# MIK32 register map
Vendor: Mikron; Series: MIK32; File version: 1.0
Registers are 32-bit, read-write, reset 0x0 unless marked. A register's access mark holds for its fields unless they carry their own. Offsets are from the block's base; [hi:lo] are bit positions.

## WakeUp — Блок WakeUp - управление питанием системным доменом, управление источниками тактовых сигналов
Base 0x00060000
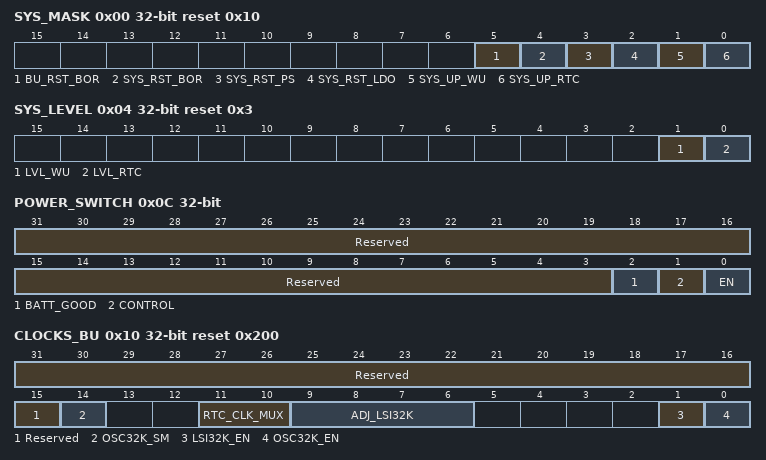
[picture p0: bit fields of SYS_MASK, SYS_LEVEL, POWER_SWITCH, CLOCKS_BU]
0x00 SYS_MASK reset 0x10 — Маски событий для включения и сброса системного домена
  [5] BU_RST_BOR — Запрещение формирования сброса батарейного домена при появлении сигнала BOR
    1=Disable (Запрещено); 0=Enable (Разрешено)
  [4] SYS_RST_BOR — Запрещение формирования сброса системного домена при появлении сигнала BOR
    1=Disable (Запрещено); 0=Enable (Разрешено)
  [3] SYS_RST_PS — Запрещение формирования сброса системного домена при снижении питания (индикация от схемы слежения)
    1=Disable (Запрещено); 0=Enable (Разрешено)
  [2] SYS_RST_LDO — Запрещение формирования сброса системного домена при снижении питания (индикация от LDO_SYS)
    1=Disable (Запрещено); 0=Enable (Разрешено)
  [1] SYS_UP_WU — Разрешение включение системного домена (из режима СТОП) при активном уровне внешнего вывода ext_wu
    0=Disable (Запрещено); 1=Enable (Разрешено)
  [0] SYS_UP_RTC — Разрешение включение системного домена (из режима СТОП) при срабатывании будильника
    0=Disable (Запрещено); 1=Enable (Разрешено)
0x04 SYS_LEVEL reset 0x3 — Активные уровни событий для включения и сброса системного домена
  [1] LVL_WU — Активный уровень внешнего вывода ext_wu
    0=Low (Активный уровень "0"); 1=High (Активный уровень "1")
  [0] LVL_RTC — Активный уровень срабатывания будильника RTC
    0=Low (Активный уровень "0"); 1=High (Активный уровень "1")
0x08 SYS_POWEROFF — Запись в регистр «1» отключает питание системного домена
0x0C POWER_SWITCH — Регистр управления и статуса схемы слежения за питанием
  [31:3] Reserved wo — Зарезервировано
  [2] BATT_GOOD ro — Флаг состояние резервного (батарейного) источника питания
  [1] CONTROL — Выбор источника напряжения VCC_BU при принудительного переключения (при En = "1")
    0=VCC (VCC - источник напряжения VCC_BU); 1=VCC_BAT (VCC_BAT - источник напряжения VCC_BU)
  [0] EN — Разрешение принудительного переключения на один из источников питания
    0=Automatic (Автоматическое переключение на один из источников питания); 1=Forced (Принудительное переключение на один из источников питания)
0x10 CLOCKS_BU reset 0x200 — Регистр управления тактированием батарейного домена
  [31:15] Reserved wo — Зарезервировано
  [14] OSC32K_SM — Режим повышенного потребления, активный уровень “0” для OSC32K. Используется для более быстрого и стабильного запуска генератора, повышает устойчивость генерации на предельных режимах эксплуатации. После запуска допускается установить значение 1.
  [11:10] RTC_CLK_MUX — Выбор приоритетного источника тактирования часов реального времени: 0x0 – автоматический выбор. При наличии обоих источников 32кГц выбирается внутренний LSI32K
    0=Automatic (Автоматический выбор. При наличии обоих источников 32кГц выбирается внутренний LSI32K); 1=LSI32K (Внутренний LSI32K); 2=OSC32K (Внешний осциллятор OSC32K)
  [9:6] ADJ_LSI32K — Поправочные коэффициенты LSI32К
  [1] LSI32K_EN — Включение/отключение LSI32К
    0=Enable (Включение LSI32К); 1=Disable (Отключение LSI32К)
  [0] OSC32K_EN — Включение/отключение внешнего осциллятора на 32 KГц
    0=Enable (Включение OSC32K); 1=Disable (Отключение OSC32K)
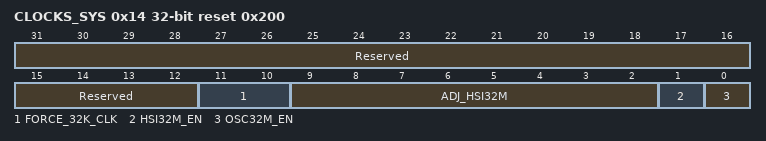
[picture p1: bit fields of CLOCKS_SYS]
0x14 CLOCKS_SYS reset 0x200 — Регистр управления тактированием системного домена
  [31:12] Reserved wo — Зарезервировано
  [11:10] FORCE_32K_CLK — Принудительное переключение на опорный источник для монитора частоты
    0=Automatic (Автоматический выбор); 1=LSI32K (Принудительно выбран LSI32K); 2=OSC32K (Принудительно выбран OSC32K); 3=Automatic (Автоматический выбор)
  [9:2] ADJ_HSI32M — Поправочные коэффициенты HSI32M
  [1] HSI32M_EN — Включение/отключение HSI32M
    0=Enable (Включение HSI32M); 1=Disable (Отключение HSI32M)
  [0] OSC32M_EN — Включение/отключение внешнего осциллятора на 32 МГц
    0=Enable (Включение OSC32M); 1=Disable (Отключение OSC32M)
0x18 RTC_CONTROL — Сброс RTC происходит при записи “1”
0x1C STOP wo — Переход в режим “Стоп”. Осуществляется записью “1” Отключает тактирования системной шины.
